# psc3m6 register map
Vendor: Infineon Technologies; Series: PSC3M6; File version: 1.0
CPU: CM33 r0p1, little endian, MPU, FPU, DSP, VTOR, 3 interrupt priority bits, 167 interrupts
Registers are 32-bit, read-write, reset 0x0 unless marked. A register's access mark holds for its fields unless they carry their own. Offsets are from the block's base; [hi:lo] are bit positions; {n}, {i} and the like mark numbered series.

## SCB0 (part 2 of 2) — Serial Communications Block (SPI/UART/I2C)
Base 0x42820000
Same registers: SCB1 0x42840000, SCB2 0x42850000, SCB3 0x42860000, SCB4 0x42870000, SCB5 0x42C00000
{0x124+0xC*i} TGS_CNT{i} (i=0..2) — Timeout generation support {i} counter
  [17:0] COUNT — 18bit counter value
{0x128+0xC*i} TGS_REL{i} (i=0..2) — Timeout generation support {i} reload
  [17:0] RELOAD — 18bit reload value for counter
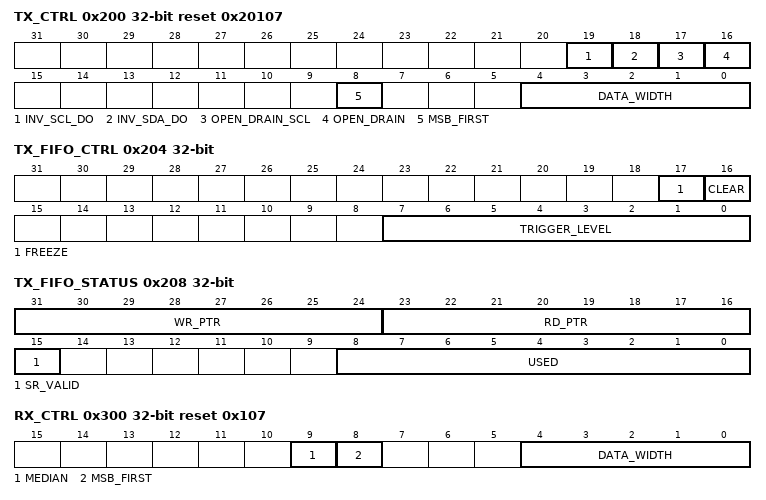
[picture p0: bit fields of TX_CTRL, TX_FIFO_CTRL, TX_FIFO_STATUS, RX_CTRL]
0x200 TX_CTRL reset 0x20107 — Transmitter control
  [19] INV_SCL_DO — 0: no inverter chosen for the I2C SCL for the 4-wire I2C 1: inverted output chosen for I2C SCL for the 4-wire I2C
  [18] INV_SDA_DO — 0': no inverter chosen for the I2C SDA for the 4-wire I2C '1': inverted output chosen for I2C SDA for the 4-wire I2C
  [17] OPEN_DRAIN_SCL — Each IO cell 'xxx' has two associated IP output signals 'xxx_out_en' and 'xxx_out'. '0': Normal operation mode. Typically, this operation mode is used for IO cells that are connected to (board) wires/lines that are driven by a single IO cell. In this operation mode, for an IO cell 'xxx' that is used as an output, the 'xxx_out_en' output enable signal is typically constant '1' the 'xxx_out' output is the outputted value. In other words, in normal operation mode, the 'xxx_out' output is used to control the IO cell output value: 'xxx_out' is '0' to drive an IO cell output value of '0' and 'xxx_out' is '1' to drive an IO cell output value of '1'. '1': Open drain operation mode. Typically this operation mode is used for IO cells that are connected to (board) wires/lines that are driven by multiple IO cells (possibly on multiple chips). In this operation mode, for and IO cell 'xxx' that is used as an output, the 'xxx_out_en' output controls the outputted value. Typically, open drain operation mode drives low/'0' and the 'xxx_out' output is constant '1'. In other words, in open drain operation mode, the 'xxx_out_en' output is used to control the IO cell output value: in drive low/'0' mode: 'xxx_out_en' is '1' (drive enabled) to drive an IO cell output value of '0' and 'xxx_out_en' is '1' (drive disabled) to not drive an IO cell output value (another IO cell can drive the wire/line or a pull up results in a wire/line value '1'). this bit is applicable to I2C SCL only. I2C SDA always work in open-drain mode. this is not applicable to M0S8, which does not need special control in SCB for open-drain drive mode.
  [16] OPEN_DRAIN — Each IO cell 'xxx' has two associated IP output signals 'xxx_out_en' and 'xxx_out'. '0': Normal operation mode. Typically, this operation mode is used for IO cells that are connected to (board) wires/lines that are driven by a single IO cell. In this operation mode, for an IO cell 'xxx' that is used as an output, the 'xxx_out_en' output enable signal is typically constant '1' the 'xxx_out' output is the outputted value. In other words, in normal operation mode, the 'xxx_out' output is used to control the IO cell output value: 'xxx_out' is '0' to drive an IO cell output value of '0' and 'xxx_out' is '1' to drive an IO cell output value of '1'. '1': Open drain operation mode. Typically this operation mode is used for IO cells that are connected to (board) wires/lines that are driven by multiple IO cells (possibly on multiple chips). In this operation mode, for and IO cell 'xxx' that is used as an output, the 'xxx_out_en' output controls the outputted value. Typically, open drain operation mode drives low/'0' and the 'xxx_out' output is constant '1'. In other words, in open drain operation mode, the 'xxx_out_en' output is used to control the IO cell output value: in drive low/'0' mode: 'xxx_out_en' is '1' (drive enabled) to drive an IO cell output value of '0' and 'xxx_out_en' is '1' (drive disabled) to not drive an IO cell output value (another IO cell can drive the wire/line or a pull up results in a wire/line value '1'). The open drain mode is supported for: - UART mode, 'uart_tx' IO cell. - SPI mode, 'spi_miso' IO cell. this bit is not applicable to I2C mode, 'i2c_scl' and 'i2c_sda' IO cells.
  [8] MSB_FIRST — Least significant bit first ('0') or most significant bit first ('1'). For I2C, this field should be '1'.
  [4:0] DATA_WIDTH — Dataframe width, depending on CTRL.MEM_WIDTH. DATA_WIDTH + 1 is the amount of bits in a transmitted data frame. This number does not include start, parity and stop bits. For UART mode, the valid range is [3, 15] for UART_STD and MP_MODE. For all other UART modes, valid range is [3 , 8]. For SPI, the valid range is [3, 31]. For I2C the only valid value is 7. In EZ mode (for both SPI and I2C), the only valid value is 7.
0x204 TX_FIFO_CTRL — Transmitter FIFO control
  [17] FREEZE — When '1', hardware reads from the transmitter FIFO do not remove FIFO entries. Freeze will not advance the TX FIFO read pointer.
  [16] CLEAR — When '1', the transmitter FIFO and transmitter shift register are cleared/invalidated. Invalidation will last for as long as this field is '1'. If a quick clear/invalidation is required, the field should be set to '1' and be followed by a set to '0'. If a clear/invalidation is required for an extended time period, the field should be set to '1' during the complete time period.
  [7:0] TRIGGER_LEVEL — Trigger level. When the transmitter FIFO has less entries than the number of this field, a transmitter trigger event INTR_TX.TRIGGER is generated.
0x208 TX_FIFO_STATUS ro — Transmitter FIFO status
  [31:24] WR_PTR — FIFO write pointer: FIFO location at which a new data frame is written.
  [23:16] RD_PTR — FIFO read pointer: FIFO location from which a data frame is read by the hardware.
  [15] SR_VALID — Indicates whether the TX shift registers holds a valid data frame ('1') or not ('0'). The shift register can be considered the top of the TX FIFO (the data frame is not included in the USED field of the TX FIFO). The shift register is a working register and holds the data frame that is currently transmitted (when the protocol state machine is transmitting a data frame) or the data frame that is transmitted next (when the protocol state machine is not transmitting a data frame).
  [8:0] USED — Amount of entries in the transmitter FIFO. The value of this field ranges from 0 to FF_DATA_NR (EZ_DATA_NR/2).
0x240 TX_FIFO_WR wo — Transmitter FIFO write
  [31:0] DATA — Data frame written into the transmitter FIFO. Behavior is similar to that of a PUSH operation. Note that when CTRL.MEM_WIDTH is '0', only DATA[7:0] are used and when CTRL.MEM_WIDTH is '1', only DATA[15:0] are used. A write to a full TX FIFO sets INTR_TX.OVERFLOW to '1'.
0x300 RX_CTRL reset 0x107 — Receiver control
  [9] MEDIAN — Median filter. When '1', a digital 3 taps median filter is performed on input interface lines. This filter should reduce the susceptibility to errors. However, its requires higher oversampling values. For UART IrDA submode, this field should always be '1'.
  [8] MSB_FIRST — Least significant bit first ('0') or most significant bit first ('1'). For I2C, this field should be '1'.
  [4:0] DATA_WIDTH — Dataframe width, depending on CTRL.MEM_WIDTH. DATA_WIDTH + 1 is the expected amount of bits in received data frame. This number does not include start, parity and stop bits. For UART mode, the valid range is [3, 15] for UART_STD. For all other UART modes, valid range is [3 , 8]. For SPI, the valid range is [3, 31]. For I2C the only valid value is 7. In EZ mode (for both SPI and I2C), the only valid value is 7.
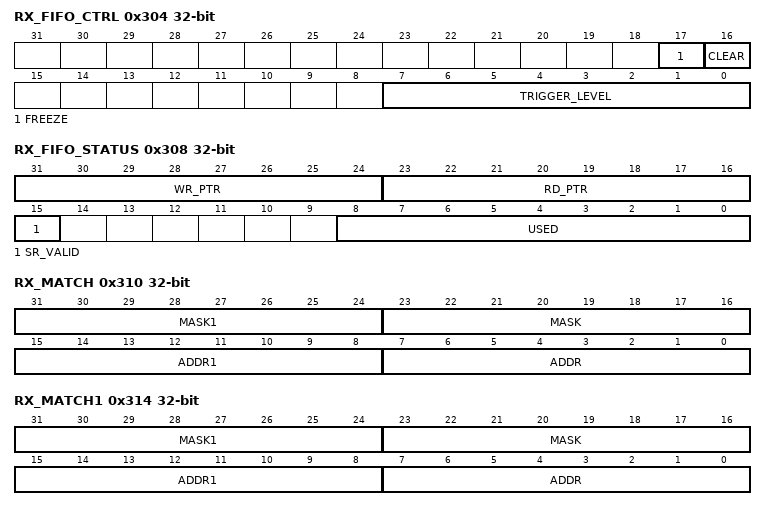
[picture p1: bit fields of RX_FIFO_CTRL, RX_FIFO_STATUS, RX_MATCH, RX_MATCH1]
0x304 RX_FIFO_CTRL — Receiver FIFO control
  [17] FREEZE — When '1', hardware writes to the receiver FIFO have no effect. Freeze will not advance the RX FIFO write pointer.
  [16] CLEAR — When '1', the receiver FIFO and receiver shift register are cleared/invalidated. Invalidation will last for as long as this field is '1'. If a quick clear/invalidation is required, the field should be set to '1' and be followed by a set to '0'. If a clear/invalidation is required for an extended time period, the field should be set to '1' during the complete time period.
  [7:0] TRIGGER_LEVEL — Trigger level. When the receiver FIFO has more entries than the number of this field, a receiver trigger event INTR_RX.TRIGGER is generated.
0x308 RX_FIFO_STATUS ro — Receiver FIFO status
  [31:24] WR_PTR — FIFO write pointer: FIFO location at which a new data frame is written by the hardware.
  [23:16] RD_PTR — FIFO read pointer: FIFO location from which a data frame is read.
  [15] SR_VALID — Indicates whether the RX shift registers holds a (partial) valid data frame ('1') or not ('0'). The shift register can be considered the bottom of the RX FIFO (the data frame is not included in the USED field of the RX FIFO). The shift register is a working register and holds the data frame that is currently being received (when the protocol state machine is receiving a data frame).
  [8:0] USED — Amount of entries in the receiver FIFO. The value of this field ranges from 0 to FF_DATA_NR (EZ_DATA_NR/2).
0x310 RX_MATCH — Slave address and mask
  [31:24] MASK1
  [23:16] MASK — Slave device address mask. This field is a mask that specifies which of the slave address bits take part in the matching. MATCH = ((ADDR & MASK) == ('slave address' & MASK)).
  [15:8] ADDR1
  [7:0] ADDR
0x314 RX_MATCH1 — Slave address and mask
  [31:24] MASK1
  [23:16] MASK — Slave device address mask. This field is a mask that specifies which of the slave address bits take part in the matching. MATCH = ((ADDR & MASK) == ('slave address' & MASK)). When this MASK is 0, the corresponding ADDR/MASK pair is disabled and does not affect address matching.
  [15:8] ADDR1
  [7:0] ADDR
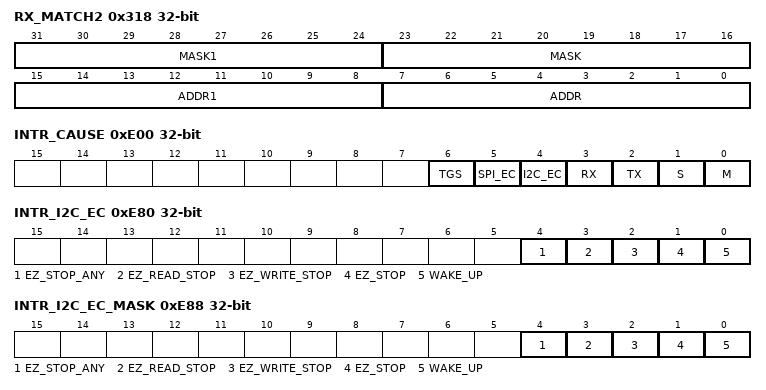
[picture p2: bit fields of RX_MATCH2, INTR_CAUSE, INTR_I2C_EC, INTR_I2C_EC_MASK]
0x318 RX_MATCH2 — Slave address and mask
  [31:24] MASK1
  [23:16] MASK — Slave device address mask. This field is a mask that specifies which of the slave address bits take part in the matching. MATCH = ((ADDR & MASK) == ('slave address' & MASK)). When MASK is 0, the corresponding ADDR/MASK pair is disabled and does not affect address matching.
  [15:8] ADDR1
  [7:0] ADDR
0x340 RX_FIFO_RD ro reset not defined — Receiver FIFO read
  [31:0] DATA — Data read from the receiver FIFO. Reading a data frame will remove the data frame from the FIFO; i.e. behavior is similar to that of a POP operation. Note that when CTRL.MEM_WIDTH is '0', only DATA[7:0] are used and when CTRL.MEM_WIDTH is '1', only DATA[15:0] are used A read from an empty RX FIFO sets INTR_RX.UNDERFLOW to '1'. When this register is read through the debugger, the data frame will not be removed from the FIFO. Similar in operation to RX_FIFO_RD_SILENT
0x344 RX_FIFO_RD_SILENT ro reset not defined — Receiver FIFO read silent
  [31:0] DATA — Data read from the receiver FIFO. Reading a data frame will NOT remove the data frame from the FIFO; i.e. behavior is similar to that of a PEEK operation. Note that when CTRL.MEM_WIDTH is '0', only DATA[7:0] are used and when CTRL.MEM_WIDTH is '1', only DATA[15:0] are used A read from an empty RX FIFO sets INTR_RX.UNDERFLOW to '1'.
0xE00 INTR_CAUSE ro — Active clocked interrupt signal
  [6] TGS — Timeout generation support interrupt ('interrupt_tgs'): INTR_TGS_MASKED != 0.
  [5] SPI_EC — Externally clocked SPI interrupt active ('interrupt_spi_ec'): INTR_SPI_EC_MASKED != 0.
  [4] I2C_EC — Externally clock I2C interrupt active ('interrupt_i2c_ec'): INTR_I2C_EC_MASKED != 0.
  [3] RX — Receiver interrupt active ('interrupt_rx'): INTR_RX_MASKED != 0.
  [2] TX — Transmitter interrupt active ('interrupt_tx'): INTR_TX_MASKED != 0.
  [1] S — Slave interrupt active ('interrupt_slave'): INTR_S_MASKED != 0.
  [0] M — Master interrupt active ('interrupt_master'): INTR_M_MASKED != 0.
0xE80 INTR_I2C_EC — Externally clocked I2C interrupt request
  [4] EZ_STOP_ANY write-1-clears
  [3] EZ_READ_STOP write-1-clears — STOP detection after a read transfer occurred. Activated on the end of a read transfer (I2C STOP). This event is an indication that a buffer memory location has been read from. Only available for a slave request with an address match, in EZ and CMD_RESP modes, when CTRL.EC_OP_MODE is '1'.
  [2] EZ_WRITE_STOP write-1-clears — STOP detection after a write transfer occurred. Activated on the end of a write transfer (I2C STOP). This event is an indication that a buffer memory location has been written to. For EZ mode: a transfer that only writes the base address does NOT activate this event. Only available for a slave request with an address match, in EZ and CMD_RESP modes, when CTRL.EC_OP_MODE is '1'.
  [1] EZ_STOP write-1-clears — STOP detection. Activated on the end of a every transfer (I2C STOP). Only available for a slave request with an address match, in EZ and CMD_RESP modes, when CTRL.EC_OP_MODE is '1'.
  [0] WAKE_UP write-1-clears — Wake up request. Active on incoming slave request (with address match). Only used when CTRL.EC_AM_MODE is '1'.
0xE88 INTR_I2C_EC_MASK — Externally clocked I2C interrupt mask
  [4] EZ_STOP_ANY — Mask bit for corresponding bit in interrupt request register.
  [3] EZ_READ_STOP — Mask bit for corresponding bit in interrupt request register.
  [2] EZ_WRITE_STOP — Mask bit for corresponding bit in interrupt request register.
  [1] EZ_STOP — Mask bit for corresponding bit in interrupt request register.
  [0] WAKE_UP — Mask bit for corresponding bit in interrupt request register.
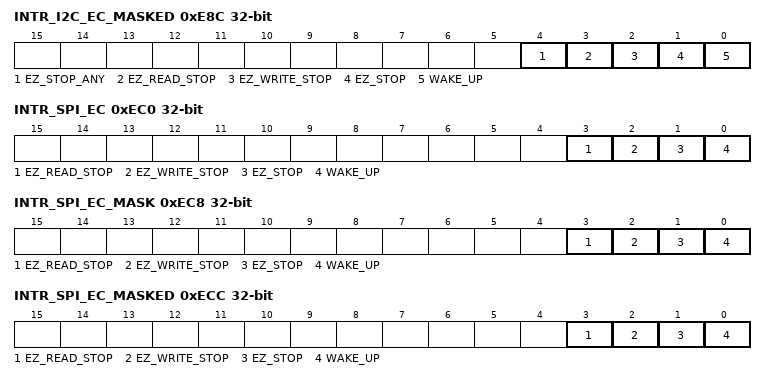
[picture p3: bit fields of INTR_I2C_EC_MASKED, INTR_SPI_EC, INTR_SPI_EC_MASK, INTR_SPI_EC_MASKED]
0xE8C INTR_I2C_EC_MASKED ro — Externally clocked I2C interrupt masked
  [4] EZ_STOP_ANY — Logical and of corresponding request and mask bits.
  [3] EZ_READ_STOP — Logical and of corresponding request and mask bits.
  [2] EZ_WRITE_STOP — Logical and of corresponding request and mask bits.
  [1] EZ_STOP — Logical and of corresponding request and mask bits.
  [0] WAKE_UP — Logical and of corresponding request and mask bits.
0xEC0 INTR_SPI_EC — Externally clocked SPI interrupt request
  [3] EZ_READ_STOP write-1-clears — STOP detection after a read transfer occurred. Activated on the end of a read transfer (SPI deselection). This event is an indication that a buffer memory location has been read from. Only used in EZ and CMD_RESP modes and when CTRL.EC_OP_MODE is '1'.
  [2] EZ_WRITE_STOP write-1-clears — STOP detection after a write transfer occurred. Activated on the end of a write transfer (SPI deselection). This event is an indication that a buffer memory location has been written to. For EZ mode: a transfer that only writes the base address does NOT activate this event. Only used in EZ and CMD_RESP modes and when CTRL.EC_OP_MODE is '1'.
  [1] EZ_STOP write-1-clears — STOP detection. Activated on the end of a every transfer (SPI deselection). Only available in EZ and CMD_RESP mode and when CTRL.EC_OP_MODE is '1'.
  [0] WAKE_UP write-1-clears — Wake up request. Active on incoming slave request when externally clocked selection is '1'. Only used when CTRL.EC_AM_MODE is '1'.
0xEC8 INTR_SPI_EC_MASK — Externally clocked SPI interrupt mask
  [3] EZ_READ_STOP — Mask bit for corresponding bit in interrupt request register.
  [2] EZ_WRITE_STOP — Mask bit for corresponding bit in interrupt request register.
  [1] EZ_STOP — Mask bit for corresponding bit in interrupt request register.
  [0] WAKE_UP — Mask bit for corresponding bit in interrupt request register.
0xECC INTR_SPI_EC_MASKED ro — Externally clocked SPI interrupt masked
  [3] EZ_READ_STOP — Logical and of corresponding request and mask bits.
  [2] EZ_WRITE_STOP — Logical and of corresponding request and mask bits.
  [1] EZ_STOP — Logical and of corresponding request and mask bits.
  [0] WAKE_UP — Logical and of corresponding request and mask bits.
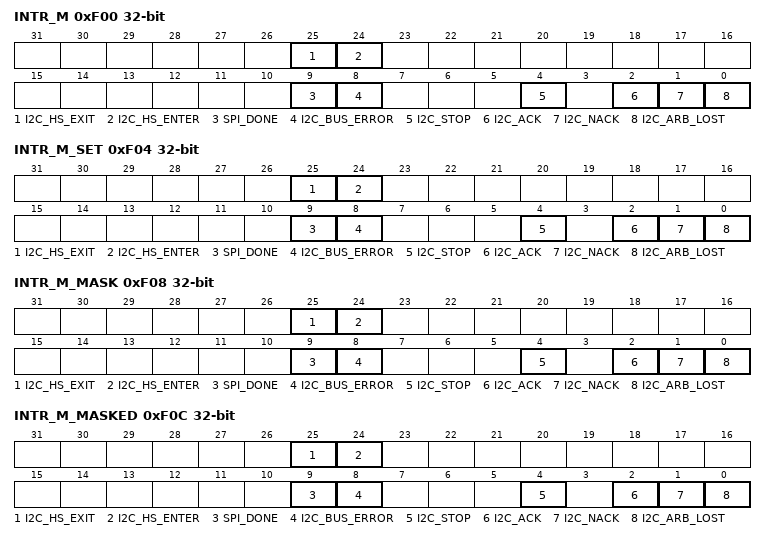
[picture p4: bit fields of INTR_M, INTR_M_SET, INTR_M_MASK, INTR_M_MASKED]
0xF00 INTR_M — Master interrupt request
  [25] I2C_HS_EXIT write-1-clears — exited I2C Hs-mode, after STOP detection.
  [24] I2C_HS_ENTER write-1-clears — entered I2C Hs-mode, at time t1, SCL falling edge after 'START, 8-bit master code (0000_1XXX), NACK' sequence.
  [9] SPI_DONE write-1-clears — SPI master transfer done event: all data frames in the transmit FIFO are sent, the transmit FIFO is empty (both TX FIFO and transmit shifter register are empty), and SPI select output pin is deselected.
  [8] I2C_BUS_ERROR write-1-clears — I2C master bus error (unexpected detection of START or STOP condition).
  [4] I2C_STOP write-1-clears — I2C master STOP. Set to '1', when the master has transmitted a STOP.
  [2] I2C_ACK write-1-clears — I2C master acknowledgement. Set to '1', when the master receives a ACK (typically after the master transmitted the slave address or TX data).
  [1] I2C_NACK write-1-clears — I2C master negative acknowledgement. Set to '1', when the master receives a NACK (typically after the master transmitted the slave address or TX data).
  [0] I2C_ARB_LOST write-1-clears — I2C master lost arbitration: the value driven by the master on the SDA line is not the same as the value observed on the SDA line. The Firmware should clear the TX FIFO, to re-do this transfer.
0xF04 INTR_M_SET — Master interrupt set request
  [25] I2C_HS_EXIT write-1-sets — Write with '1' to set corresponding bit in interrupt request register.
  [24] I2C_HS_ENTER write-1-sets — Write with '1' to set corresponding bit in interrupt request register.
  [9] SPI_DONE write-1-sets — Write with '1' to set corresponding bit in interrupt request register.
  [8] I2C_BUS_ERROR write-1-sets — Write with '1' to set corresponding bit in interrupt request register.
  [4] I2C_STOP write-1-sets — Write with '1' to set corresponding bit in interrupt request register.
  [2] I2C_ACK write-1-sets — Write with '1' to set corresponding bit in interrupt request register.
  [1] I2C_NACK write-1-sets — Write with '1' to set corresponding bit in interrupt request register.
  [0] I2C_ARB_LOST write-1-sets — Write with '1' to set corresponding bit in interrupt request register.
0xF08 INTR_M_MASK — Master interrupt mask
  [25] I2C_HS_EXIT — Mask bit for corresponding bit in interrupt request register.
  [24] I2C_HS_ENTER — Mask bit for corresponding bit in interrupt request register.
  [9] SPI_DONE — Mask bit for corresponding bit in interrupt request register.
  [8] I2C_BUS_ERROR — Mask bit for corresponding bit in interrupt request register.
  [4] I2C_STOP — Mask bit for corresponding bit in interrupt request register.
  [2] I2C_ACK — Mask bit for corresponding bit in interrupt request register.
  [1] I2C_NACK — Mask bit for corresponding bit in interrupt request register.
  [0] I2C_ARB_LOST — Mask bit for corresponding bit in interrupt request register.
0xF0C INTR_M_MASKED ro — Master interrupt masked request
  [25] I2C_HS_EXIT — Logical and of corresponding request and mask bits.
  [24] I2C_HS_ENTER — Logical and of corresponding request and mask bits.
  [9] SPI_DONE — Logical and of corresponding request and mask bits.
  [8] I2C_BUS_ERROR — Logical and of corresponding request and mask bits.
  [4] I2C_STOP — Logical and of corresponding request and mask bits.
  [2] I2C_ACK — Logical and of corresponding request and mask bits.
  [1] I2C_NACK — Logical and of corresponding request and mask bits.
  [0] I2C_ARB_LOST — Logical and of corresponding request and mask bits.
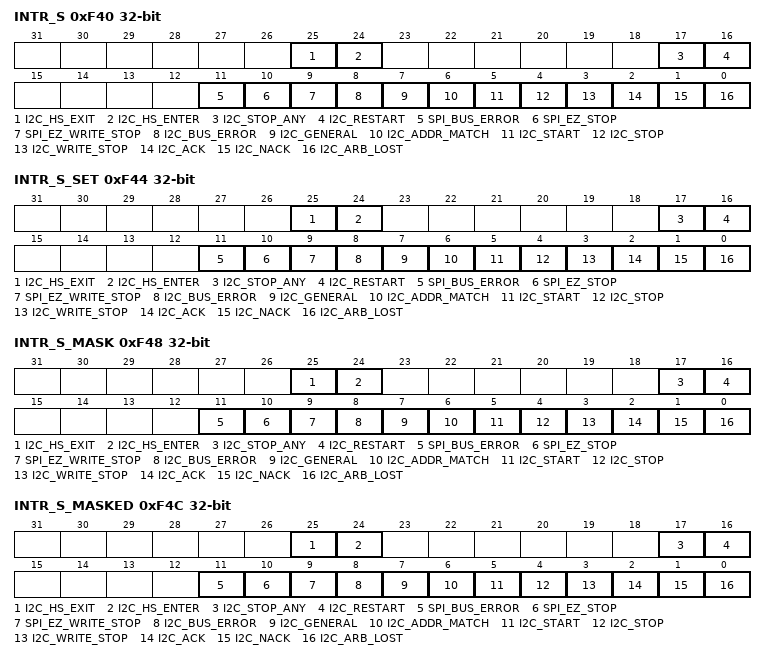
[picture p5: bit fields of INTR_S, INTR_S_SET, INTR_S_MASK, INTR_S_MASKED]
0xF40 INTR_S — Slave interrupt request
  [25] I2C_HS_EXIT write-1-clears
  [24] I2C_HS_ENTER write-1-clears
  [17] I2C_STOP_ANY write-1-clears
  [16] I2C_RESTART write-1-clears
  [11] SPI_BUS_ERROR write-1-clears
  [10] SPI_EZ_STOP write-1-clears
  [9] SPI_EZ_WRITE_STOP write-1-clears
  [8] I2C_BUS_ERROR write-1-clears
  [7] I2C_GENERAL write-1-clears
  [6] I2C_ADDR_MATCH write-1-clears
  [5] I2C_START write-1-clears
  [4] I2C_STOP write-1-clears
  [3] I2C_WRITE_STOP write-1-clears
  [2] I2C_ACK write-1-clears
  [1] I2C_NACK write-1-clears
  [0] I2C_ARB_LOST write-1-clears — I2C slave lost arbitration: the value driven on the SDA line is not the same as the value observed on the SDA line (while the SCL line is '1'). This should not occur, it represents erroneous I2C bus behavior. In case of lost arbitration, the I2C slave state machine aborts the ongoing transfer. The Firmware may decide to clear the TX and RX FIFOs in case of this error.
0xF44 INTR_S_SET — Slave interrupt set request
  [25] I2C_HS_EXIT write-1-sets — Write with '1' to set corresponding bit in interrupt request register.
  [24] I2C_HS_ENTER write-1-sets — Write with '1' to set corresponding bit in interrupt request register.
  [17] I2C_STOP_ANY write-1-sets — Write with '1' to set corresponding bit in interrupt request register.
  [16] I2C_RESTART write-1-sets — Write with '1' to set corresponding bit in interrupt request register.
  [11] SPI_BUS_ERROR write-1-sets — Write with '1' to set corresponding bit in interrupt request register.
  [10] SPI_EZ_STOP write-1-sets — Write with '1' to set corresponding bit in interrupt request register.
  [9] SPI_EZ_WRITE_STOP write-1-sets — Write with '1' to set corresponding bit in interrupt request register.
  [8] I2C_BUS_ERROR write-1-sets — Write with '1' to set corresponding bit in interrupt request register.
  [7] I2C_GENERAL write-1-sets — Write with '1' to set corresponding bit in interrupt request register.
  [6] I2C_ADDR_MATCH write-1-sets — Write with '1' to set corresponding bit in interrupt request register.
  [5] I2C_START write-1-sets — Write with '1' to set corresponding bit in interrupt request register.
  [4] I2C_STOP write-1-sets — Write with '1' to set corresponding bit in interrupt request register.
  [3] I2C_WRITE_STOP write-1-sets — Write with '1' to set corresponding bit in interrupt request register.
  [2] I2C_ACK write-1-sets — Write with '1' to set corresponding bit in interrupt request register.
  [1] I2C_NACK write-1-sets — Write with '1' to set corresponding bit in interrupt request register.
  [0] I2C_ARB_LOST write-1-sets — Write with '1' to set corresponding bit in interrupt request register.
0xF48 INTR_S_MASK — Slave interrupt mask
  [25] I2C_HS_EXIT — Mask bit for corresponding bit in interrupt request register.
  [24] I2C_HS_ENTER — Mask bit for corresponding bit in interrupt request register.
  [17] I2C_STOP_ANY — Mask bit for corresponding bit in interrupt request register.
  [16] I2C_RESTART — Mask bit for corresponding bit in interrupt request register.
  [11] SPI_BUS_ERROR — Mask bit for corresponding bit in interrupt request register.
  [10] SPI_EZ_STOP — Mask bit for corresponding bit in interrupt request register.
  [9] SPI_EZ_WRITE_STOP — Mask bit for corresponding bit in interrupt request register.
  [8] I2C_BUS_ERROR — Mask bit for corresponding bit in interrupt request register.
  [7] I2C_GENERAL — Mask bit for corresponding bit in interrupt request register.
  [6] I2C_ADDR_MATCH — Mask bit for corresponding bit in interrupt request register.
  [5] I2C_START — Mask bit for corresponding bit in interrupt request register.
  [4] I2C_STOP — Mask bit for corresponding bit in interrupt request register.
  [3] I2C_WRITE_STOP — Mask bit for corresponding bit in interrupt request register.
  [2] I2C_ACK — Mask bit for corresponding bit in interrupt request register.
  [1] I2C_NACK — Mask bit for corresponding bit in interrupt request register.
  [0] I2C_ARB_LOST — Mask bit for corresponding bit in interrupt request register.
0xF4C INTR_S_MASKED ro — Slave interrupt masked request
  [25] I2C_HS_EXIT — Logical and of corresponding request and mask bits.
  [24] I2C_HS_ENTER — Logical and of corresponding request and mask bits.
  [17] I2C_STOP_ANY — Logical and of corresponding request and mask bits.
  [16] I2C_RESTART — Logical and of corresponding request and mask bits.
  [11] SPI_BUS_ERROR — Logical and of corresponding request and mask bits.
  [10] SPI_EZ_STOP — Logical and of corresponding request and mask bits.
  [9] SPI_EZ_WRITE_STOP — Logical and of corresponding request and mask bits.
  [8] I2C_BUS_ERROR — Logical and of corresponding request and mask bits.
  [7] I2C_GENERAL — Logical and of corresponding request and mask bits.
  [6] I2C_ADDR_MATCH — Logical and of corresponding request and mask bits.
  [5] I2C_START — Logical and of corresponding request and mask bits.
  [4] I2C_STOP — Logical and of corresponding request and mask bits.
  [3] I2C_WRITE_STOP — Logical and of corresponding request and mask bits.
  [2] I2C_ACK — Logical and of corresponding request and mask bits.
  [1] I2C_NACK — Logical and of corresponding request and mask bits.
  [0] I2C_ARB_LOST — Logical and of corresponding request and mask bits.
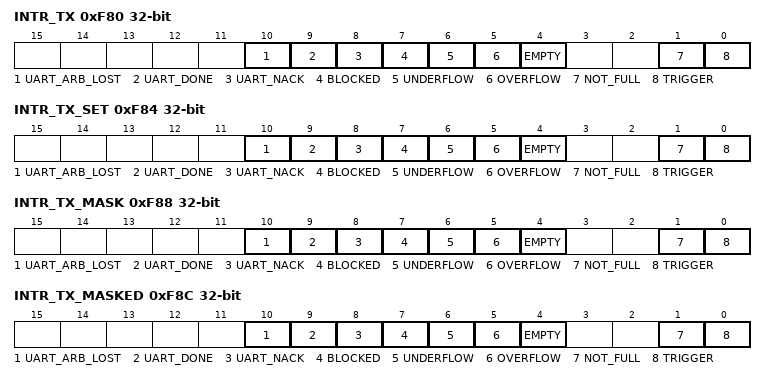
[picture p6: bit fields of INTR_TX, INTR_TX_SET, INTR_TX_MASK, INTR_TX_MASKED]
0xF80 INTR_TX — Transmitter interrupt request
  [10] UART_ARB_LOST write-1-clears
  [9] UART_DONE write-1-clears
  [8] UART_NACK write-1-clears
  [7] BLOCKED write-1-clears — SW cannot get access to the EZ memory (EZ data access), due to an externally clocked EZ access. This may happen when STATUS.EC_BUSY is '1'.
  [6] UNDERFLOW write-1-clears — Attempt to read from an empty TX FIFO. This happens when SCB is ready to transfer data and EMPTY is '1'. Only used in FIFO mode.
  [5] OVERFLOW write-1-clears
  [4] EMPTY write-1-clears
  [1] NOT_FULL write-1-clears
  [0] TRIGGER write-1-clears
0xF84 INTR_TX_SET — Transmitter interrupt set request
  [10] UART_ARB_LOST write-1-sets — Write with '1' to set corresponding bit in interrupt request register.
  [9] UART_DONE write-1-sets — Write with '1' to set corresponding bit in interrupt request register.
  [8] UART_NACK write-1-sets — Write with '1' to set corresponding bit in interrupt request register.
  [7] BLOCKED write-1-sets — Write with '1' to set corresponding bit in interrupt request register.
  [6] UNDERFLOW write-1-sets — Write with '1' to set corresponding bit in interrupt request register.
  [5] OVERFLOW write-1-sets — Write with '1' to set corresponding bit in interrupt request register.
  [4] EMPTY write-1-sets — Write with '1' to set corresponding bit in interrupt request register.
  [1] NOT_FULL write-1-sets — Write with '1' to set corresponding bit in interrupt request register.
  [0] TRIGGER write-1-sets — Write with '1' to set corresponding bit in interrupt request register.
0xF88 INTR_TX_MASK — Transmitter interrupt mask
  [10] UART_ARB_LOST — Mask bit for corresponding bit in interrupt request register.
  [9] UART_DONE — Mask bit for corresponding bit in interrupt request register.
  [8] UART_NACK — Mask bit for corresponding bit in interrupt request register.
  [7] BLOCKED — Mask bit for corresponding bit in interrupt request register.
  [6] UNDERFLOW — Mask bit for corresponding bit in interrupt request register.
  [5] OVERFLOW — Mask bit for corresponding bit in interrupt request register.
  [4] EMPTY — Mask bit for corresponding bit in interrupt request register.
  [1] NOT_FULL — Mask bit for corresponding bit in interrupt request register.
  [0] TRIGGER — Mask bit for corresponding bit in interrupt request register.
0xF8C INTR_TX_MASKED ro — Transmitter interrupt masked request
  [10] UART_ARB_LOST — Logical and of corresponding request and mask bits.
  [9] UART_DONE — Logical and of corresponding request and mask bits.
  [8] UART_NACK — Logical and of corresponding request and mask bits.
  [7] BLOCKED — Logical and of corresponding request and mask bits.
  [6] UNDERFLOW — Logical and of corresponding request and mask bits.
  [5] OVERFLOW — Logical and of corresponding request and mask bits.
  [4] EMPTY — Logical and of corresponding request and mask bits.
  [1] NOT_FULL — Logical and of corresponding request and mask bits.
  [0] TRIGGER — Logical and of corresponding request and mask bits.
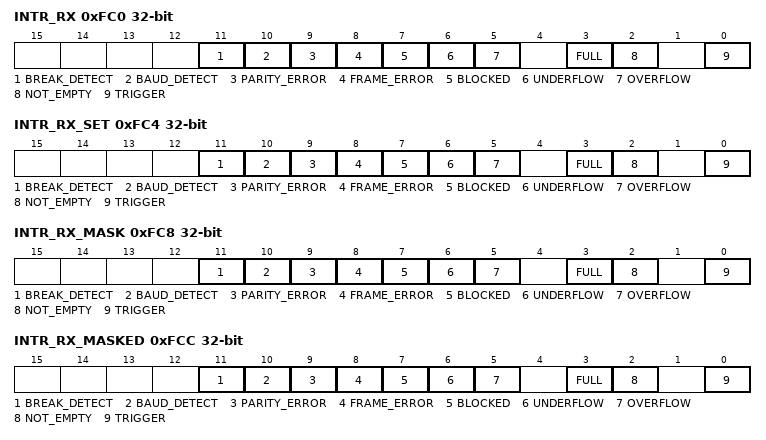
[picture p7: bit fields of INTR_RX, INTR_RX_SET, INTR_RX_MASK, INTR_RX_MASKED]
0xFC0 INTR_RX — Receiver interrupt request
  [11] BREAK_DETECT write-1-clears
  [10] BAUD_DETECT write-1-clears
  [9] PARITY_ERROR write-1-clears
  [8] FRAME_ERROR write-1-clears
  [7] BLOCKED write-1-clears — SW cannot get access to the EZ memory (EZ_DATA accesses), due to an externally clocked EZ access. This may happen when STATUS.EC_BUSY is '1'.
  [6] UNDERFLOW write-1-clears
  [5] OVERFLOW write-1-clears
  [3] FULL write-1-clears
  [2] NOT_EMPTY write-1-clears
  [0] TRIGGER write-1-clears
0xFC4 INTR_RX_SET — Receiver interrupt set request
  [11] BREAK_DETECT write-1-sets — Write with '1' to set corresponding bit in interrupt status register.
  [10] BAUD_DETECT write-1-sets — Write with '1' to set corresponding bit in interrupt status register.
  [9] PARITY_ERROR write-1-sets — Write with '1' to set corresponding bit in interrupt status register.
  [8] FRAME_ERROR write-1-sets — Write with '1' to set corresponding bit in interrupt status register.
  [7] BLOCKED write-1-sets — Write with '1' to set corresponding bit in interrupt status register.
  [6] UNDERFLOW write-1-sets — Write with '1' to set corresponding bit in interrupt status register.
  [5] OVERFLOW write-1-sets — Write with '1' to set corresponding bit in interrupt status register.
  [3] FULL write-1-sets — Write with '1' to set corresponding bit in interrupt status register.
  [2] NOT_EMPTY write-1-sets — Write with '1' to set corresponding bit in interrupt status register.
  [0] TRIGGER write-1-sets — Write with '1' to set corresponding bit in interrupt request register.
0xFC8 INTR_RX_MASK — Receiver interrupt mask
  [11] BREAK_DETECT — Mask bit for corresponding bit in interrupt request register.
  [10] BAUD_DETECT — Mask bit for corresponding bit in interrupt request register.
  [9] PARITY_ERROR — Mask bit for corresponding bit in interrupt request register.
  [8] FRAME_ERROR — Mask bit for corresponding bit in interrupt request register.
  [7] BLOCKED — Mask bit for corresponding bit in interrupt request register.
  [6] UNDERFLOW — Mask bit for corresponding bit in interrupt request register.
  [5] OVERFLOW — Mask bit for corresponding bit in interrupt request register.
  [3] FULL — Mask bit for corresponding bit in interrupt request register.
  [2] NOT_EMPTY — Mask bit for corresponding bit in interrupt request register.
  [0] TRIGGER — Mask bit for corresponding bit in interrupt request register.
0xFCC INTR_RX_MASKED ro — Receiver interrupt masked request
  [11] BREAK_DETECT — Logical and of corresponding request and mask bits.
  [10] BAUD_DETECT — Logical and of corresponding request and mask bits.
  [9] PARITY_ERROR — Logical and of corresponding request and mask bits.
  [8] FRAME_ERROR — Logical and of corresponding request and mask bits.
  [7] BLOCKED — Logical and of corresponding request and mask bits.
  [6] UNDERFLOW — Logical and of corresponding request and mask bits.
  [5] OVERFLOW — Logical and of corresponding request and mask bits.
  [3] FULL — Logical and of corresponding request and mask bits.
  [2] NOT_EMPTY — Logical and of corresponding request and mask bits.
  [0] TRIGGER — Logical and of corresponding request and mask bits.
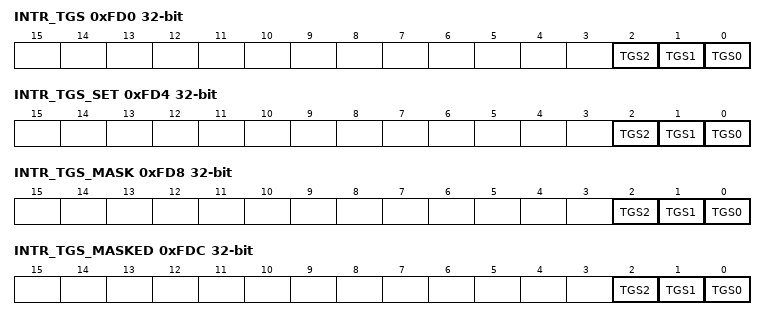
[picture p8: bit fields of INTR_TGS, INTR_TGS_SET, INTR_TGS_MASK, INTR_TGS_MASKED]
0xFD0 INTR_TGS — Receiver interrupt request
  [2] TGS2 write-1-clears, [1] TGS1 write-1-clears, [0] TGS0 write-1-clears
0xFD4 INTR_TGS_SET — Receiver interrupt set request
  [2] TGS2 write-1-sets — Write with '1' to set corresponding bit in interrupt status register.
  [1] TGS1 write-1-sets — Write with '1' to set corresponding bit in interrupt status register.
  [0] TGS0 write-1-sets — Write with '1' to set corresponding bit in interrupt request register.
0xFD8 INTR_TGS_MASK — Receiver interrupt mask
  [2] TGS2 — Mask bit for corresponding bit in interrupt request register.
  [1] TGS1 — Mask bit for corresponding bit in interrupt request register.
  [0] TGS0 — Mask bit for corresponding bit in interrupt request register.
0xFDC INTR_TGS_MASKED ro — Receiver interrupt masked request
  [2] TGS2 — Logical and of corresponding request and mask bits.
  [1] TGS1 — Logical and of corresponding request and mask bits.
  [0] TGS0 — Logical and of corresponding request and mask bits.
